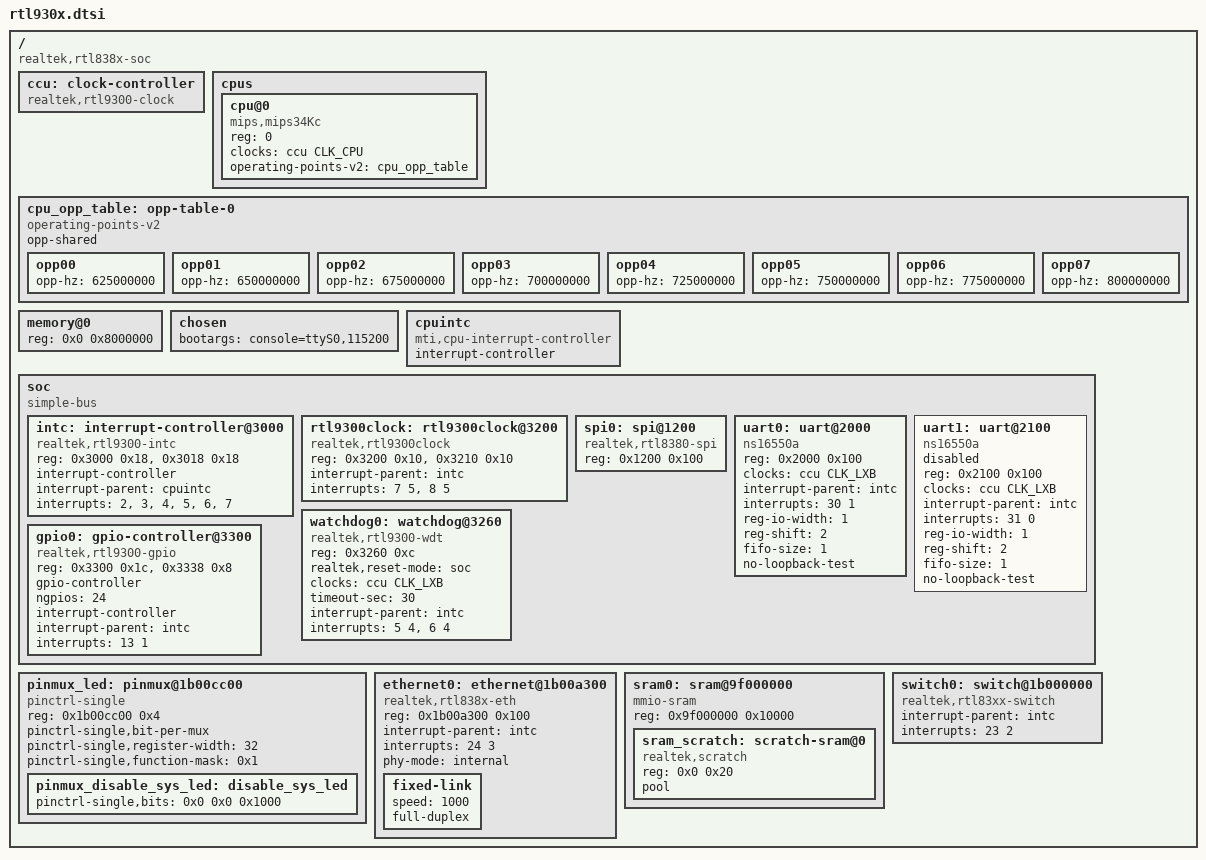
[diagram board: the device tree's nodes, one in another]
// SPDX-License-Identifier: GPL-2.0-or-later OR MIT

#include <dt-bindings/clock/rtl83xx-clk.h>

/dts-v1/;

/ {
	#address-cells = <1>;
	#size-cells = <1>;

	compatible = "realtek,rtl838x-soc";

	ccu: clock-controller {
		compatible = "realtek,rtl9300-clock";
		#clock-cells = <1>;
	};

	cpus {
		#address-cells = <1>;
		#size-cells = <0>;

		cpu@0 {
			compatible = "mips,mips34Kc";
			reg = <0>;
			clocks = <&ccu CLK_CPU>;
			operating-points-v2 = <&cpu_opp_table>;
		};
	};

	cpu_opp_table: opp-table-0 {
		compatible = "operating-points-v2";
		opp-shared;

		opp00 {
			opp-hz = /bits/ 64 <625000000>;
		};
		opp01 {
			opp-hz = /bits/ 64 <650000000>;
		};
		opp02 {
			opp-hz = /bits/ 64 <675000000>;
		};
		opp03 {
			opp-hz = /bits/ 64 <700000000>;
		};
		opp04 {
			opp-hz = /bits/ 64 <725000000>;
		};
		opp05 {
			opp-hz = /bits/ 64 <750000000>;
		};
		opp06 {
			opp-hz = /bits/ 64 <775000000>;
		};
		opp07 {
			opp-hz = /bits/ 64 <800000000>;
		};
	};

	memory@0 {
		device_type = "memory";
		reg = <0x0 0x8000000>;
	};

	chosen {
		bootargs = "console=ttyS0,115200";
	};

	cpuintc: cpuintc {
		compatible = "mti,cpu-interrupt-controller";
		#address-cells = <0>;
		#interrupt-cells = <1>;
		interrupt-controller;
	};

	soc: soc {
		compatible = "simple-bus";
		#address-cells = <1>;
		#size-cells = <1>;
		ranges = <0x0 0x18000000 0x10000>;

		intc: interrupt-controller@3000 {
			compatible = "realtek,rtl9300-intc", "realtek,rtl-intc";
			reg = <0x3000 0x18>, <0x3018 0x18>;
			interrupt-controller;
			#interrupt-cells = <2>;

			interrupt-parent = <&cpuintc>;
			interrupts = <2>, <3>, <4>, <5>, <6>, <7>;
		};

		rtl9300clock: rtl9300clock@3200 {
			compatible = "realtek,rtl9300clock";
			reg = <0x3200 0x10>, <0x3210 0x10>;

			interrupt-parent = <&intc>;
			interrupts = <7 5>, <8 5>;
		};

		spi0: spi@1200 {
			compatible = "realtek,rtl8380-spi";
			reg = <0x1200 0x100>;

			#address-cells = <1>;
			#size-cells = <0>;
		};

		uart0: uart@2000 {
			compatible = "ns16550a";
			reg = <0x2000 0x100>;

			clocks = <&ccu CLK_LXB>;

			interrupt-parent = <&intc>;
			interrupts = <30 1>;

			reg-io-width = <1>;
			reg-shift = <2>;
			fifo-size = <1>;
			no-loopback-test;
		};

		uart1: uart@2100 {
			compatible = "ns16550a";
			reg = <0x2100 0x100>;

			clocks = <&ccu CLK_LXB>;

			interrupt-parent = <&intc>;
			interrupts = <31 0>;

			reg-io-width = <1>;
			reg-shift = <2>;
			fifo-size = <1>;
			no-loopback-test;

			status = "disabled";
		};

		watchdog0: watchdog@3260 {
			compatible = "realtek,rtl9300-wdt";
			reg = <0x3260 0xc>;

			realtek,reset-mode = "soc";

			clocks = <&ccu CLK_LXB>;
			timeout-sec = <30>;

			interrupt-parent = <&intc>;
			interrupt-names = "phase1", "phase2";
			interrupts = <5 4>, <6 4>;
		};

		gpio0: gpio-controller@3300 {
			compatible = "realtek,rtl9300-gpio", "realtek,otto-gpio";
			reg = <0x3300 0x1c>, <0x3338 0x8>;

			gpio-controller;
			#gpio-cells = <2>;
			ngpios = <24>;

			interrupt-controller;
			#interrupt-cells = <2>;
			interrupt-parent = <&intc>;
			interrupts = <13 1>;
		};

	};

	pinmux_led: pinmux@1b00cc00 {
		compatible = "pinctrl-single";
		reg = <0x1b00cc00 0x4>;

		pinctrl-single,bit-per-mux;
		pinctrl-single,register-width = <32>;
		pinctrl-single,function-mask = <0x1>;
		#pinctrl-cells = <2>;

		/* enable GPIO 0 */
		pinmux_disable_sys_led: disable_sys_led {
			pinctrl-single,bits = <0x0 0x0 0x1000>;
		};
	};

	ethernet0: ethernet@1b00a300 {
		compatible = "realtek,rtl838x-eth";
		reg = <0x1b00a300 0x100>;

		interrupt-parent = <&intc>;
		interrupts = <24 3>;

		phy-mode = "internal";

		fixed-link {
			speed = <1000>;
			full-duplex;
		};
	};

	sram0: sram@9f000000 {
		compatible = "mmio-sram";
		reg = <0x9f000000 0x10000>;
		#address-cells = <1>;
		#size-cells = <1>;
		ranges = <0 0x9f000000 0x10000>;

		sram_scratch: scratch-sram@0 {
			compatible = "realtek,scratch";
			reg = <0x0 0x20>;
			pool;
		};
	};

	switch0: switch@1b000000 {
		compatible = "realtek,rtl83xx-switch";
		status = "okay";

		interrupt-parent = <&intc>;
		interrupts = <23 2>;
	};
};
